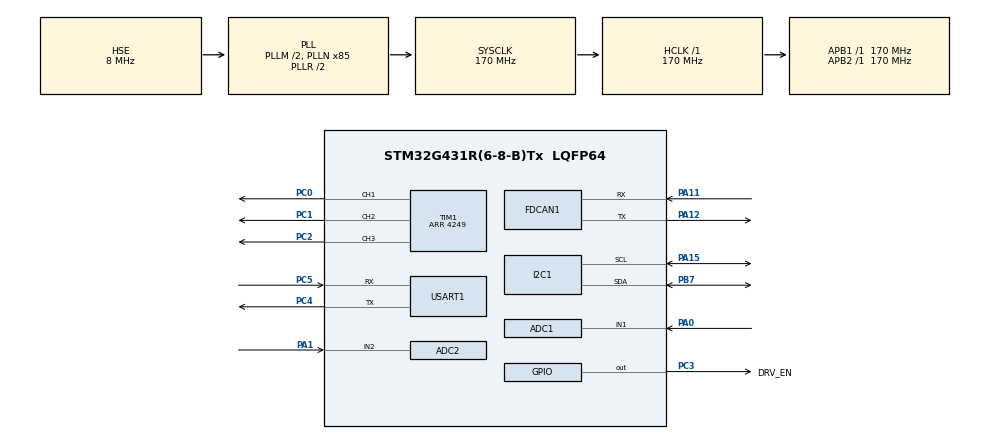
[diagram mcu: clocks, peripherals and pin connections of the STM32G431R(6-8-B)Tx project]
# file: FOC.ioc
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ADC1.Channel-0\#ChannelRegularConversion=ADC_CHANNEL_1
ADC1.NbrOfConversionFlag=1
ADC1.OffsetNumber-0\#ChannelRegularConversion=ADC_OFFSET_NONE
ADC1.Rank-0\#ChannelRegularConversion=1
ADC1.SamplingTime-0\#ChannelRegularConversion=ADC_SAMPLETIME_2CYCLES_5
ADC1.master=1
ADC2.Channel-0\#ChannelRegularConversion=ADC_CHANNEL_2
ADC2.NbrOfConversionFlag=1
ADC2.OffsetNumber-0\#ChannelRegularConversion=ADC_OFFSET_NONE
ADC2.Rank-0\#ChannelRegularConversion=1
ADC2.SamplingTime-0\#ChannelRegularConversion=ADC_SAMPLETIME_2CYCLES_5
FDCAN1.CalculateBaudRateNominal=3541666
FDCAN1.CalculateTimeBitNominal=282
FDCAN1.CalculateTimeQuantumNominal=94.11764705882354
I2C1.Timing=0x40B285C2
Mcu.Family=STM32G4
Mcu.Name=STM32G431R(6-8-B)Tx
Mcu.Package=LQFP64
NVIC.PriorityGroup=NVIC_PRIORITYGROUP_4
NVIC.TIM6_DAC_IRQn=true\:0\:0\:false\:false\:true\:true\:true\:true
PA0.Mode=IN1-Single-Ended
PA0.Signal=ADC1_IN1
PA1.Mode=IN2-Single-Ended
PA1.Signal=ADC2_IN2
PA11.Mode=FDCAN_Activate
PA11.Signal=FDCAN1_RX
PA12.Mode=FDCAN_Activate
PA12.Signal=FDCAN1_TX
PA13.Mode=Serial_Wire
PA13.Signal=SYS_JTMS-SWDIO
PA14.Mode=Serial_Wire
PA14.Signal=SYS_JTCK-SWCLK
PA15.Mode=I2C
PA15.Signal=I2C1_SCL
PB7.Mode=I2C
PB7.Signal=I2C1_SDA
PC0.Signal=S_TIM1_CH1
PC1.Signal=S_TIM1_CH2
PC2.Signal=S_TIM1_CH3
PC3.GPIO_Label=DRV_EN
PC3.Signal=GPIO_Output
PC4.Mode=Asynchronous
PC4.Signal=USART1_TX
PC5.Mode=Asynchronous
PC5.Signal=USART1_RX
PF0-OSC_IN.Mode=HSE-External-Oscillator
PF0-OSC_IN.Signal=RCC_OSC_IN
PF1-OSC_OUT.Mode=HSE-External-Oscillator
PF1-OSC_OUT.Signal=RCC_OSC_OUT
ProjectManager.HeapSize=0x200
ProjectManager.StackSize=0x400
ProjectManager.TargetToolchain=CMake
RCC.ADC12Freq_Value=170000000
RCC.AHBFreq_Value=170000000
RCC.APB1Freq_Value=170000000
RCC.APB1TimFreq_Value=170000000
RCC.APB2Freq_Value=170000000
RCC.APB2TimFreq_Value=170000000
RCC.CortexFreq_Value=170000000
RCC.EXTERNAL_CLOCK_VALUE=12288000
RCC.HCLKFreq_Value=170000000
RCC.HSE_VALUE=8000000
RCC.HSI48_VALUE=48000000
RCC.HSI_VALUE=16000000
RCC.LSE_VALUE=32768
RCC.PLLM=RCC_PLLM_DIV2
RCC.PLLN=85
RCC.PLLSourceVirtual=RCC_PLLSOURCE_HSE
RCC.SYSCLKFreq_VALUE=170000000
RCC.SYSCLKSource=RCC_SYSCLKSOURCE_PLLCLK
RCC.USBFreq_Value=170000000
RCC.VCOOutputFreq_Value=340000000
SH.S_TIM1_CH1.0=TIM1_CH1,PWM Generation1 CH1
SH.S_TIM1_CH2.0=TIM1_CH2,PWM Generation2 CH2
SH.S_TIM1_CH3.0=TIM1_CH3,PWM Generation3 CH3
TIM1.Channel-PWM\ Generation1\ CH1=TIM_CHANNEL_1
TIM1.Channel-PWM\ Generation2\ CH2=TIM_CHANNEL_2
TIM1.Channel-PWM\ Generation3\ CH3=TIM_CHANNEL_3
TIM1.CounterMode=TIM_COUNTERMODE_CENTERALIGNED1
TIM1.PeriodNoDither=4249
TIM6.PeriodNoDither=999
TIM6.Prescaler=169
USART1.VirtualMode-Asynchronous=VM_ASYNC
VP_SYS_VS_DBSignals.Mode=DisableDeadBatterySignals
VP_TIM6_VS_ClockSourceINT.Mode=Enable_Timer
board=custom

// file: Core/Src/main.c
/* USER CODE BEGIN Header */
/**
  ******************************************************************************
  * @file           : main.c
  * @brief          : Main program body
  ******************************************************************************
  * @attention
  *
  * Copyright (c) 2026 STMicroelectronics.
  * All rights reserved.
  *
  * This software is licensed under terms that can be found in the LICENSE file
  * in the root directory of this software component.
  * If no LICENSE file comes with this software, it is provided AS-IS.
  *
  ******************************************************************************
  */
/* USER CODE END Header */
#include "main.h"
#include "adc.h"
#include "fdcan.h"
#include "i2c.h"
#include "tim.h"
#include "usart.h"
#include "gpio.h"

/* USER CODE BEGIN Includes */
#include "tsk_config_and_callback.h"
#include "AS5600_APP.h"
#include "uart_printf.h"
/* USER CODE END Includes */

void SystemClock_Config(void);

int main(void)
{

  /* MCU Configuration--------------------------------------------------------*/

  /* Reset of all peripherals, Initializes the Flash interface and the Systick. */
  HAL_Init();

  /* Configure the system clock */
  SystemClock_Config();

  /* Initialize all configured peripherals */
  MX_GPIO_Init();
  MX_ADC1_Init();
  MX_ADC2_Init();
  MX_FDCAN1_Init();
  MX_I2C1_Init();
  MX_TIM1_Init();
  MX_USART1_UART_Init();
  MX_TIM6_Init();
  /* USER CODE BEGIN 2 */

  Task_Init();
  /* USER CODE END 2 */

  /* Infinite loop */
  /* USER CODE BEGIN WHILE */
  while (1)
  {
    Task_loop();
    /* USER CODE END WHILE */

  }
}

void SystemClock_Config(void)
{
  RCC_OscInitTypeDef RCC_OscInitStruct = {0};
  RCC_ClkInitTypeDef RCC_ClkInitStruct = {0};

  /** Configure the main internal regulator output voltage
  */
  HAL_PWREx_ControlVoltageScaling(PWR_REGULATOR_VOLTAGE_SCALE1_BOOST);

  /** Initializes the RCC Oscillators according to the specified parameters
  * in the RCC_OscInitTypeDef structure.
  */
  RCC_OscInitStruct.OscillatorType = RCC_OSCILLATORTYPE_HSE;
  RCC_OscInitStruct.HSEState = RCC_HSE_ON;
  RCC_OscInitStruct.PLL.PLLState = RCC_PLL_ON;
  RCC_OscInitStruct.PLL.PLLSource = RCC_PLLSOURCE_HSE;
  RCC_OscInitStruct.PLL.PLLM = RCC_PLLM_DIV2;
  RCC_OscInitStruct.PLL.PLLN = 85;
  RCC_OscInitStruct.PLL.PLLP = RCC_PLLP_DIV2;
  RCC_OscInitStruct.PLL.PLLQ = RCC_PLLQ_DIV2;
  RCC_OscInitStruct.PLL.PLLR = RCC_PLLR_DIV2;
  if (HAL_RCC_OscConfig(&RCC_OscInitStruct) != HAL_OK)
  {
    Error_Handler();
  }

  /** Initializes the CPU, AHB and APB buses clocks
  */
  RCC_ClkInitStruct.ClockType = RCC_CLOCKTYPE_HCLK|RCC_CLOCKTYPE_SYSCLK
                              |RCC_CLOCKTYPE_PCLK1|RCC_CLOCKTYPE_PCLK2;
  RCC_ClkInitStruct.SYSCLKSource = RCC_SYSCLKSOURCE_PLLCLK;
  RCC_ClkInitStruct.AHBCLKDivider = RCC_SYSCLK_DIV1;
  RCC_ClkInitStruct.APB1CLKDivider = RCC_HCLK_DIV1;
  RCC_ClkInitStruct.APB2CLKDivider = RCC_HCLK_DIV1;

  if (HAL_RCC_ClockConfig(&RCC_ClkInitStruct, FLASH_LATENCY_4) != HAL_OK)
  {
    Error_Handler();
  }
}

void Error_Handler(void)
{
  __disable_irq();
  while (1)
  {
  }
}
